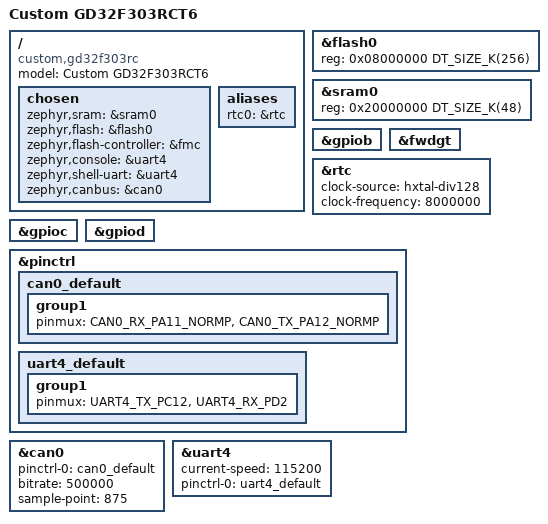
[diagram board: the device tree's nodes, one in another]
/dts-v1/;
#include <gd/gd32f30x/gd32f303.dtsi>
#include <dt-bindings/pinctrl/gd32f303r(b)xx-pinctrl.h>

/ {
	model = "Custom GD32F303RCT6";
	compatible = "custom,gd32f303rc";
	chosen {
		zephyr,sram = &sram0;
		zephyr,flash = &flash0;
		zephyr,flash-controller = &fmc;
		zephyr,console = &uart4;
		zephyr,shell-uart = &uart4;
		zephyr,canbus = &can0;
	};
	aliases {
		rtc0 = &rtc;
	};
};

&flash0 { reg = <0x08000000 DT_SIZE_K(256)>; };
&sram0 { reg = <0x20000000 DT_SIZE_K(48)>; };
&gpiob { status = "okay"; };
&fwdgt { status = "okay"; };
&rtc {
	status = "okay";
	clock-source = "hxtal-div128";
	clock-frequency = <8000000>;
};
&gpioc { status = "okay"; };
&gpiod { status = "okay"; };
&pinctrl {
	can0_default: can0_default {
		group1 {
			pinmux = <CAN0_RX_PA11_NORMP>, <CAN0_TX_PA12_NORMP>;
		};
	};

	uart4_default: uart4_default {
		group1 {
			pinmux = <UART4_TX_PC12>, <UART4_RX_PD2>;
		};
	};
};

&can0 {
	status = "okay";
	pinctrl-0 = <&can0_default>;
	pinctrl-names = "default";
	bitrate = <500000>;
	sample-point = <875>;
};
&uart4 {
	status = "okay";
	current-speed = <115200>;
	pinctrl-0 = <&uart4_default>;
	pinctrl-names = "default";
};

#include "partitions.dtsi"
#include "precharge.dtsi"
